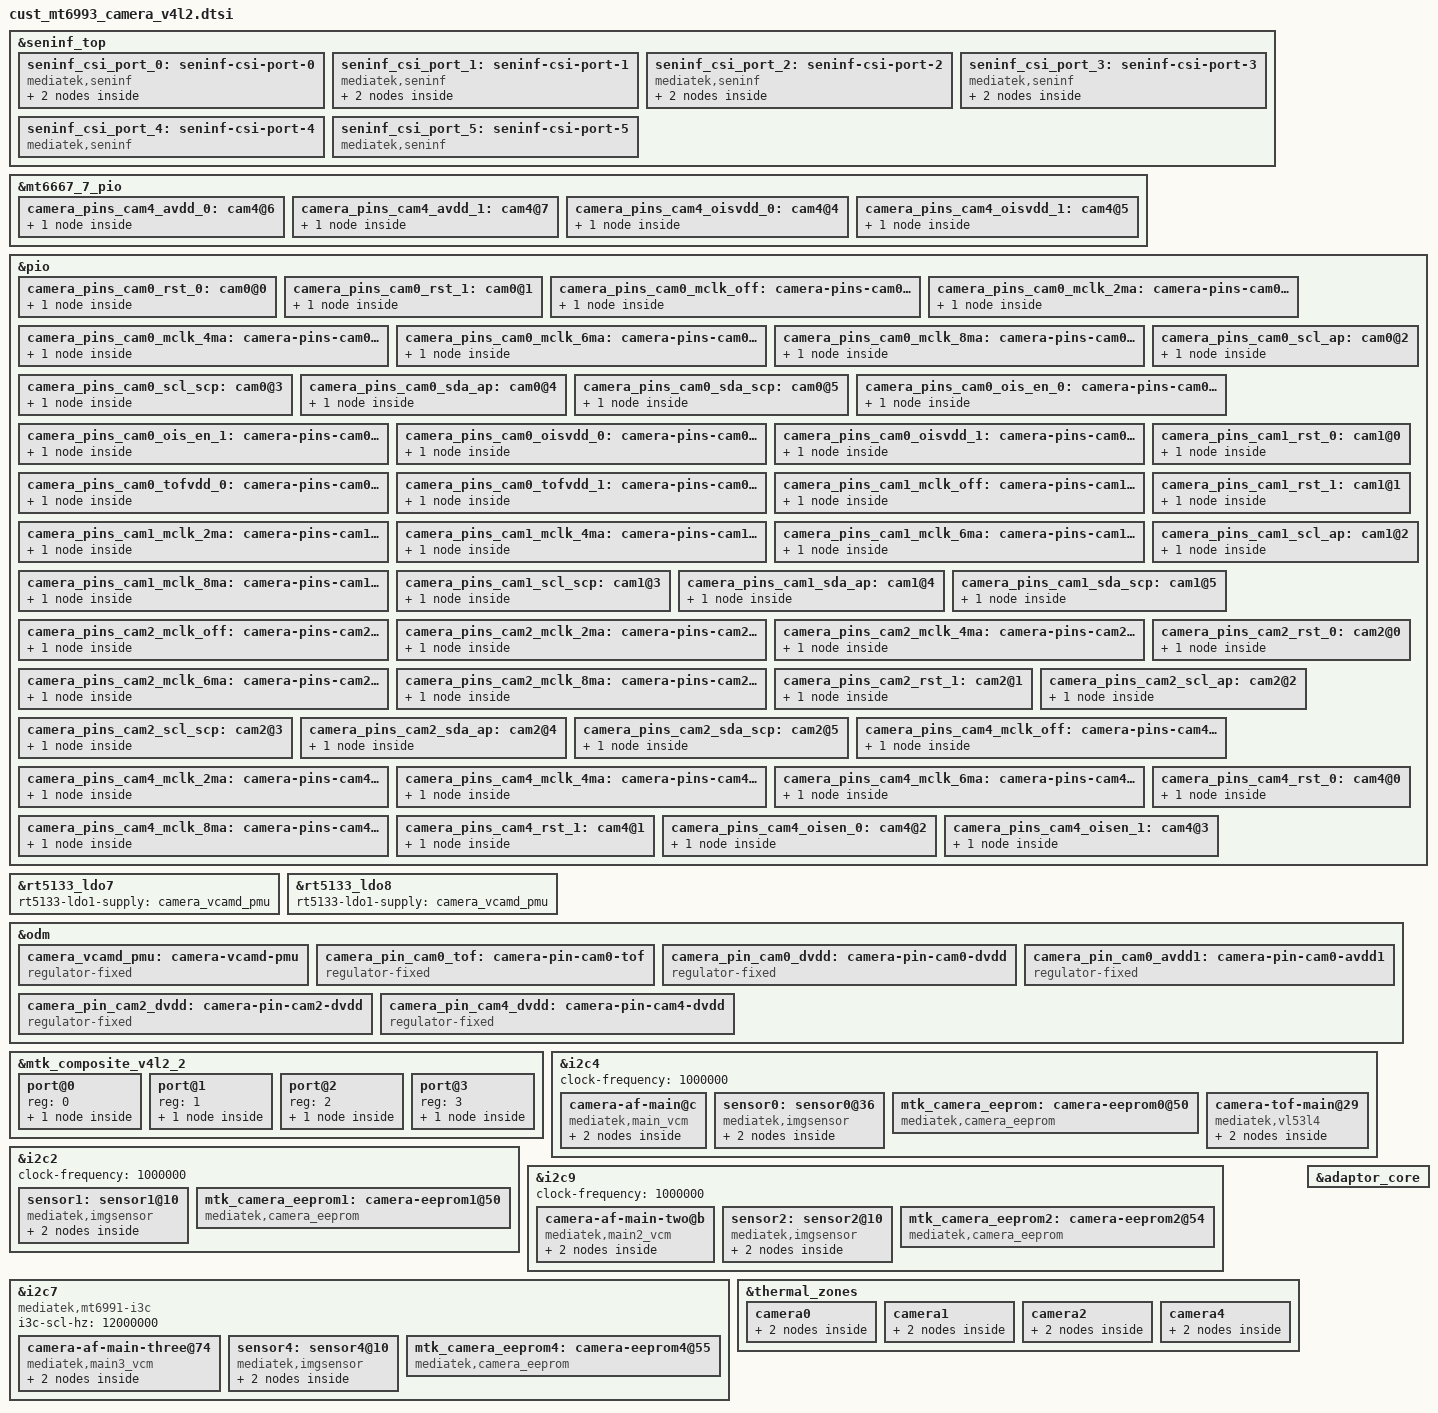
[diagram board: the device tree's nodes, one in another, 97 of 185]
// SPDX-License-Identifier: GPL-2.0
/* Copyright (c) 2023 MediaTek Inc. */
#include <dt-bindings/clock/mt6993-clk.h>
#include <dt-bindings/pinctrl/mt6993-pinfunc.h>
#include <dt-bindings/pinctrl/mt6667-pinfunc.h>

#if 0
&aov {
	depend-on = <&seninf_csi_port_0>,
		<&seninf_csi_port_1>,
		<&seninf_csi_port_2>,
		<&seninf_csi_port_3>,
		<&seninf_csi_port_4>;
};
#endif

&seninf_top {
		seninf_csi_port_0: seninf-csi-port-0 {
			compatible = "mediatek,seninf";
			csi-port = "0";

			nvmem-cells = <&csi_efuse0>;
			nvmem-cell-names = "rg_csi";
			port {
				seninf_csi_port_0_in: endpoint {
					remote-endpoint = <&sensor1_out>;
				};
			};
		};

		seninf_csi_port_1: seninf-csi-port-1 {
			compatible = "mediatek,seninf";
			csi-port = "1";

			nvmem-cells = <&csi_efuse1>;
			nvmem-cell-names = "rg_csi";

			/* HP9 EINT */
			interrupts-extended = <&pio 187 IRQ_TYPE_EDGE_FALLING>;
			gpio-num = <187>;
			eint-no = <3>; /* Max to 3, options:{1, 2, 3} */

			port {
				seninf_csi_port_1_in: endpoint {
					remote-endpoint = <&sensor4_out>;
				};
			};
		};

		seninf_csi_port_2: seninf-csi-port-2 {
			compatible = "mediatek,seninf";
			csi-port = "2";

			nvmem-cells = <&csi_efuse2>;
			nvmem-cell-names = "rg_csi";

			/* JN1 EINT */
			interrupts-extended = <&pio 186 IRQ_TYPE_EDGE_FALLING>;
			gpio-num = <186>;
			eint-no = <2>; /* Max to 3, options:{1, 2, 3} */

			port {
				seninf_csi_port_2_in: endpoint {
					remote-endpoint = <&sensor2_out>;
				};
			};
		};
		seninf_csi_port_3: seninf-csi-port-3 {
			compatible = "mediatek,seninf";
			csi-port = "3";

			nvmem-cells = <&csi_efuse3>;
			nvmem-cell-names = "rg_csi";

			/* KOKU EINT */
			interrupts-extended = <&pio 185 IRQ_TYPE_EDGE_FALLING>;
			gpio-num = <185>;
			eint-no = <1>; /* Max to 3, options:{1, 2, 3} */

			port {
				seninf_csi_port_3_in: endpoint@1 {
					remote-endpoint = <&sensor0_out>;
				};
			};
		};
		seninf_csi_port_4: seninf-csi-port-4 {
			compatible = "mediatek,seninf";
			csi-port = "4";

			nvmem-cells = <&csi_efuse4>;
			nvmem-cell-names = "rg_csi";
		};
		seninf_csi_port_5: seninf-csi-port-5 {
			compatible = "mediatek,seninf";
			csi-port = "5";

			nvmem-cells = <&csi_efuse5>;
			nvmem-cell-names = "rg_csi";
		};
};

&mt6667_7_pio {
	camera_pins_cam4_avdd_0: cam4@6 {
		pins-1 {
			pinmux = <PINMUX_MT6667_GPIO1__FUNC_GPIO1>;
			drive-strengh = <15>;
			output-low;
		};
	};

	camera_pins_cam4_avdd_1: cam4@7 {
		pins-1 {
			pinmux = <PINMUX_MT6667_GPIO1__FUNC_GPIO1>;
			drive-strengh = <15>;
			output-high;
		};
	};

	camera_pins_cam4_oisvdd_0: cam4@4 {
		pins-1 {
			pinmux = <PINMUX_MT6667_GPIO4__FUNC_GPIO4>;
			drive-strengh = <15>;
			output-low;
		};
	};
	camera_pins_cam4_oisvdd_1: cam4@5 {
		pins-1 {
			pinmux = <PINMUX_MT6667_GPIO4__FUNC_GPIO4>;
			drive-strengh = <15>;
			output-high;
		};
	};
};


&pio {
	camera_pins_cam0_rst_0: cam0@0 {
		pins-cmd-dat {
			pinmux = <PINMUX_GPIO206__FUNC_GPIO206>;
			slew-rate = <1>;
			output-low;
		};
	};

	camera_pins_cam0_rst_1: cam0@1 {
		pins-cmd-dat {
			pinmux = <PINMUX_GPIO206__FUNC_GPIO206>;
			slew-rate = <1>;
			output-high;
		};
	};

	camera_pins_cam0_mclk_off: camera-pins-cam0-mclk-off {
		pins-cmd-dat {
			pinmux = <PINMUX_GPIO73__FUNC_GPIO73>;
			drive-strength = <1>;
		};
	};

	camera_pins_cam0_mclk_2ma: camera-pins-cam0-mclk-2ma {
		pins-cmd-dat {
			pinmux = <PINMUX_GPIO73__FUNC_CMMCLK1>;
			drive-strength = <0>;
		};
	};

	camera_pins_cam0_mclk_4ma: camera-pins-cam0-mclk-4ma {
		pins-cmd-dat {
			pinmux = <PINMUX_GPIO73__FUNC_CMMCLK1>;
			drive-strength = <1>;
		};
	};

	camera_pins_cam0_mclk_6ma: camera-pins-cam0-mclk-6ma {
		pins-cmd-dat {
			pinmux = <PINMUX_GPIO73__FUNC_CMMCLK1>;
			drive-strength = <2>;
		};
	};

	camera_pins_cam0_mclk_8ma: camera-pins-cam0-mclk-8ma {
		pins-cmd-dat {
			pinmux = <PINMUX_GPIO73__FUNC_CMMCLK1>;
			drive-strength = <3>;
		};
	};

	camera_pins_cam0_scl_ap: cam0@2 {
		pins-cmd-dat {
			pinmux = <PINMUX_GPIO174__FUNC_SCL4>;
		};
	};
	camera_pins_cam0_scl_scp: cam0@3 {
		pins-cmd-dat {
			pinmux = <PINMUX_GPIO174__FUNC_SCP_SCL9>;
		};
	};
	camera_pins_cam0_sda_ap: cam0@4 {
		pins-cmd-dat {
			pinmux = <PINMUX_GPIO175__FUNC_SDA4>;
		};
	};
	camera_pins_cam0_sda_scp: cam0@5 {
		pins-cmd-dat {
			pinmux = <PINMUX_GPIO175__FUNC_SCP_SDA9>;
		};
	};
	camera_pins_cam0_ois_en_0: camera-pins-cam0-ois-en-0 {
		pins-cmd-dat {
			pinmux = <PINMUX_GPIO154__FUNC_GPIO154>;
			slew-rate = <1>;
			output-low;
		};
	};
	camera_pins_cam0_ois_en_1: camera-pins-cam0-ois-en-1 {
		pins-cmd-dat {
			pinmux = <PINMUX_GPIO154__FUNC_GPIO154>;
			slew-rate = <1>;
			output-high;
		};
	};
	camera_pins_cam0_oisvdd_0: camera-pins-cam0-oisvdd-0 {
		pins-cmd-dat {
			pinmux = <PINMUX_GPIO217__FUNC_GPIO217>;
			slew-rate = <1>;
			output-low;
		};
	};
	camera_pins_cam0_oisvdd_1: camera-pins-cam0-oisvdd-1 {
		pins-cmd-dat {
			pinmux = <PINMUX_GPIO217__FUNC_GPIO217>;
			slew-rate = <1>;
			output-high;
		};
	};
	camera_pins_cam0_tofvdd_0: camera-pins-cam0-tofvdd-0 {
		pins-cmd-dat {
			pinmux = <PINMUX_GPIO183__FUNC_GPIO183>;
			slew-rate = <1>;
			output-low;
		};
	};
	camera_pins_cam0_tofvdd_1: camera-pins-cam0-tofvdd-1 {
		pins-cmd-dat {
			pinmux = <PINMUX_GPIO183__FUNC_GPIO183>;
			slew-rate = <1>;
			output-high;
		};
	};
	camera_pins_cam1_mclk_off: camera-pins-cam1-mclk-off {
		pins-cmd-dat {
			pinmux = <PINMUX_GPIO72__FUNC_GPIO72>;
			drive-strength = <1>;
		};
	};
	camera_pins_cam1_mclk_2ma: camera-pins-cam1-mclk-2ma {
		pins-cmd-dat {
			pinmux = <PINMUX_GPIO72__FUNC_CMMCLK0>;
			drive-strength = <0>;
		};
	};
	camera_pins_cam1_mclk_4ma: camera-pins-cam1-mclk-4ma {
		pins-cmd-dat {
			pinmux = <PINMUX_GPIO72__FUNC_CMMCLK0>;
			drive-strength = <1>;
		};
	};
	camera_pins_cam1_mclk_6ma: camera-pins-cam1-mclk-6ma {
		pins-cmd-dat {
			pinmux = <PINMUX_GPIO72__FUNC_CMMCLK0>;
			drive-strength = <2>;
		};
	};
	camera_pins_cam1_mclk_8ma: camera-pins-cam1-mclk-8ma {
		pins-cmd-dat {
			pinmux = <PINMUX_GPIO72__FUNC_CMMCLK0>;
			drive-strength = <3>;
		};
	};
	camera_pins_cam1_rst_0: cam1@0 {
		pins-cmd-dat {
			pinmux = <PINMUX_GPIO205__FUNC_GPIO205>;
			slew-rate = <1>;
			output-low;
		};
	};
	camera_pins_cam1_rst_1: cam1@1 {
		pins-cmd-dat {
			pinmux = <PINMUX_GPIO205__FUNC_GPIO205>;
			slew-rate = <1>;
			output-high;
		};
	};
	camera_pins_cam1_scl_ap: cam1@2 {
		pins-cmd-dat {
			pinmux = <PINMUX_GPIO172__FUNC_SCL2>;
		};
	};
	camera_pins_cam1_scl_scp: cam1@3 {
		pins-cmd-dat {
			pinmux = <PINMUX_GPIO172__FUNC_SCP_SCL8>;
		};
	};
	camera_pins_cam1_sda_ap: cam1@4 {
		pins-cmd-dat {
			pinmux = <PINMUX_GPIO173__FUNC_SDA2>;
		};
	};
	camera_pins_cam1_sda_scp: cam1@5 {
		pins-cmd-dat {
			pinmux = <PINMUX_GPIO173__FUNC_SCP_SDA8>;
		};
	};
	camera_pins_cam2_mclk_off: camera-pins-cam2-mclk-off {
		pins-cmd-dat {
			pinmux = <PINMUX_GPIO208__FUNC_GPIO208>;
			drive-strength = <1>;
		};
	};
	camera_pins_cam2_mclk_2ma: camera-pins-cam2-mclk-2ma {
		pins-cmd-dat {
			pinmux = <PINMUX_GPIO208__FUNC_CMMCLK4>;
			drive-strength = <0>;
		};
	};
	camera_pins_cam2_mclk_4ma: camera-pins-cam2-mclk-4ma {
		pins-cmd-dat {
			pinmux = <PINMUX_GPIO208__FUNC_CMMCLK4>;
			drive-strength = <1>;
		};
	};
	camera_pins_cam2_mclk_6ma: camera-pins-cam2-mclk-6ma {
		pins-cmd-dat {
			pinmux = <PINMUX_GPIO208__FUNC_CMMCLK4>;
			drive-strength = <2>;
		};
	};
	camera_pins_cam2_mclk_8ma: camera-pins-cam2-mclk-8ma {
		pins-cmd-dat {
			pinmux = <PINMUX_GPIO208__FUNC_CMMCLK4>;
			drive-strength = <3>;
		};
	};
	camera_pins_cam2_rst_0: cam2@0 {
		pins-cmd-dat {
			pinmux = <PINMUX_GPIO207__FUNC_GPIO207>;
			slew-rate = <1>;
			output-low;
		};
	};
	camera_pins_cam2_rst_1: cam2@1 {
		pins-cmd-dat {
			pinmux = <PINMUX_GPIO207__FUNC_GPIO207>;
			slew-rate = <1>;
			output-high;
		};
	};
	camera_pins_cam2_scl_ap: cam2@2 {
		pins-cmd-dat {
			pinmux = <PINMUX_GPIO200__FUNC_SCL9>;
		};
	};
	camera_pins_cam2_scl_scp: cam2@3 {
		pins-cmd-dat {
			pinmux = <PINMUX_GPIO200__FUNC_SCP_SCL7>;
		};
	};
	camera_pins_cam2_sda_ap: cam2@4 {
		pins-cmd-dat {
			pinmux = <PINMUX_GPIO201__FUNC_SDA9>;
		};
	};
	camera_pins_cam2_sda_scp: cam2@5 {
		pins-cmd-dat {
			pinmux = <PINMUX_GPIO201__FUNC_SCP_SDA7>;
		};
	};
	camera_pins_cam4_mclk_off: camera-pins-cam4-mclk-off {
		pins-cmd-dat {
			pinmux = <PINMUX_GPIO188__FUNC_GPIO188>;
			drive-strength = <1>;
		};
	};
	camera_pins_cam4_mclk_2ma: camera-pins-cam4-mclk-2ma {
		pins-cmd-dat {
			pinmux = <PINMUX_GPIO188__FUNC_CMMCLK2>;
			drive-strength = <0>;
		};
	};
	camera_pins_cam4_mclk_4ma: camera-pins-cam4-mclk-4ma {
		pins-cmd-dat {
			pinmux = <PINMUX_GPIO188__FUNC_CMMCLK2>;
			drive-strength = <1>;
		};
	};
	camera_pins_cam4_mclk_6ma: camera-pins-cam4-mclk-6ma {
		pins-cmd-dat {
			pinmux = <PINMUX_GPIO188__FUNC_CMMCLK2>;
			drive-strength = <2>;
		};
	};
	camera_pins_cam4_mclk_8ma: camera-pins-cam4-mclk-8ma {
		pins-cmd-dat {
			pinmux = <PINMUX_GPIO188__FUNC_CMMCLK2>;
			drive-strength = <3>;
		};
	};
	camera_pins_cam4_rst_0: cam4@0 {
		pins-cmd-dat {
			pinmux = <PINMUX_GPIO189__FUNC_GPIO189>;
			slew-rate = <1>;
			output-low;
		};
	};
	camera_pins_cam4_rst_1: cam4@1 {
		pins-cmd-dat {
			pinmux = <PINMUX_GPIO189__FUNC_GPIO189>;
			slew-rate = <1>;
			output-high;
		};
	};
	camera_pins_cam4_oisen_0: cam4@2 {
		pins-cmd-dat {
			pinmux = <PINMUX_GPIO155__FUNC_GPIO155>;
			slew-rate = <1>;
			output-low;
		};
	};
	camera_pins_cam4_oisen_1: cam4@3 {
		pins-cmd-dat {
			pinmux = <PINMUX_GPIO155__FUNC_GPIO155>;
			slew-rate = <1>;
			output-high;
		};
	};
};

&rt5133_ldo7 {
	rt5133-ldo1-supply = <&camera_vcamd_pmu>;
};

&rt5133_ldo8 {
	rt5133-ldo1-supply = <&camera_vcamd_pmu>;
};

&odm {
	camera_vcamd_pmu: camera-vcamd-pmu {
		compatible = "regulator-fixed";
		regulator-name = "amera-vcamd-pmu";
		regulator-min-microvolt = <1800000>;
		regulator-max-microvolt = <1800000>;
		enable-active-high;
		gpio = <&pio 182 0x0>;
	};

	camera_pin_cam0_tof:camera-pin-cam0-tof {
		compatible = "regulator-fixed";
		regulator-name = "camera-pin-cam0-tof";
		regulator-min-microvolt = <1800000>;
		regulator-max-microvolt = <1800000>;
		enable-active-high;
		gpio = <&pio 184 0x0>;
	};

	camera_pin_cam0_dvdd:camera-pin-cam0-dvdd {
		compatible = "regulator-fixed";
		regulator-name = "camera-pin-cam0-dvdd";
		regulator-min-microvolt = <1800000>;
		regulator-max-microvolt = <1800000>;
		enable-active-high;
		gpio = <&pio 192 0x0>;
	};

	camera_pin_cam0_avdd1:camera-pin-cam0-avdd1 {
		compatible = "regulator-fixed";
		regulator-name = "camera-pin-cam0-avdd1";
		regulator-min-microvolt = <1800000>;
		regulator-max-microvolt = <1800000>;
		enable-active-high;
		gpio = <&pio 193 0x0>;
	};

	camera_pin_cam2_dvdd:camera-pin-cam2-dvdd {
		compatible = "regulator-fixed";
		regulator-name = "camera-pin-cam2-dvdd";
		regulator-min-microvolt = <1800000>;
		regulator-max-microvolt = <1800000>;
		enable-active-high;
		gpio = <&pio 212 0x0>;
	};

	camera_pin_cam4_dvdd:camera-pin-cam4-dvdd {
		compatible = "regulator-fixed";
		regulator-name = "camera-pin-cam4-dvdd";
		regulator-min-microvolt = <1800000>;
		regulator-max-microvolt = <1800000>;
		enable-active-high;
		gpio = <&pio 215 0x0>;
	};
};

&mtk_composite_v4l2_2 {
	#address-cells = <1>;
	#size-cells = <0>;
	port@0 {
		reg = <0>;
		main_af_endpoint: endpoint {
			remote-endpoint = <&main_af>;
		};
	};
	port@1 {
		reg = <1>;
		main_af_cam1_endpoint: endpoint {
			remote-endpoint = <&main_af_cam1>;
		};
	};
	port@2 {
		reg = <2>;
		main_af_cam2_endpoint: endpoint {
			remote-endpoint = <&main_af_cam2>;
		};
	};
	port@3 {
		reg = <3>;
		main_tof_endpoint: endpoint {
			remote-endpoint = <&main_tof>;
		};
	};
};

&i2c4 {
	status = "okay";
	clock-frequency = <1000000>;

	camera-af-main@c {
		compatible = "mediatek,main_vcm";
		reg = <0x0c 0 0>;
		vin-supply = <&rt5133_gpio1>;
		port {
			main_af: endpoint {
				remote-endpoint = <&main_af_endpoint>;
			};
		};
	};

	sensor0: sensor0@36 {
		compatible = "mediatek,imgsensor";
		sensor-names = "ov48b_mipi_raw",
					"imx06a_mipi_raw",
					"imx06c_mipi_raw";
		reg = <0x36 0 0>;
		maximum-pmic-delay = <4000>;

		#thermal-sensor-cells = <0>;

		pinctrl-names = "mclk_off",
				"mclk_2mA",
				"mclk_4mA",
				"mclk_6mA",
				"mclk_8mA",
				"rst_low",
				"rst_high",
				"scl_ap",
				"scl_scp",
				"sda_ap",
				"sda_scp",
				"oisvdd_off",
				"oisvdd_on",
				"oisen_off",
				"oisen_on";
		pinctrl-0 = <&camera_pins_cam0_mclk_off>;
		pinctrl-1 = <&camera_pins_cam0_mclk_2ma>;
		pinctrl-2 = <&camera_pins_cam0_mclk_4ma>;
		pinctrl-3 = <&camera_pins_cam0_mclk_6ma>;
		pinctrl-4 = <&camera_pins_cam0_mclk_8ma>;
		pinctrl-5 = <&camera_pins_cam0_rst_0>;
		pinctrl-6 = <&camera_pins_cam0_rst_1>;
		pinctrl-7 = <&camera_pins_cam0_scl_ap>;
		pinctrl-8 = <&camera_pins_cam0_scl_scp>;
		pinctrl-9 = <&camera_pins_cam0_sda_ap>;
		pinctrl-10 = <&camera_pins_cam0_sda_scp>;
		pinctrl-11 = <&camera_pins_cam0_oisvdd_0>;
		pinctrl-12 = <&camera_pins_cam0_oisvdd_1>;
		pinctrl-13 = <&camera_pins_cam0_ois_en_0>;
		pinctrl-14 = <&camera_pins_cam0_ois_en_1>;

		avdd-supply =  <&rt5133_ldo5>;  // 2.8V
		avdd1-supply =  <&camera_pin_cam0_avdd1>;  // 1.8V
		dvdd-supply = <&rt5133_ldo7>;  // 1.1v for ov48b
		dvdd1-supply = <&camera_pin_cam0_dvdd>;  // 0.81v for tri cam
		afvdd1-supply = <&rt5133_gpio1>;
		dovdd-supply = <&camera_vcamd_pmu>;  // iovdd 1.8v share
		base-supply = <&rt5133_base>;

		clocks = <&cksys_top_clk CKSYS_TOP_UNIVPLL_192M_D32>,
			<&cksys_top_clk CKSYS_TOP_UNIVPLL_192M_D16>,
			<&cksys_top_clk CKSYS_VLP_F26M_CK_D2>,
			<&cksys_top_clk CKSYS_TOP_UNIVPLL_192M_D10>,
			<&cksys_top_clk CKSYS_TOP_UNIVPLL_192M_D8>,
			<&cksys_top_clk CKSYS_TOP_UNIVPLL_D6_D16>,
			<&cksys_vlp_clk CKSYS_VLP_OSC3>,
			<&cksys_top_clk CKSYS_TOP_UNIVPLL_D6_D8>,
			<&cksys_vlp_clk VLP_CAMTG1_SEL>;

		clock-names = "6", "12", "13", "19.2", "24", "26", "26_ulposc", "52", "mclk";


		status = "okay";
		port {
			sensor0_out: endpoint {
				remote-endpoint = <&seninf_csi_port_3_in>;
			};
		};
	};

	mtk_camera_eeprom:camera-eeprom0@50 {
		compatible = "mediatek,camera_eeprom";
		reg = <0x50 0 0>;
		names = "imx06c_cust_eeprom",
			"ov48b_mtk_eeprom";
		status = "okay";
	};

	camera-tof-main@29 {
		compatible = "mediatek,vl53l4";
		reg = <0x29 0 0>;
		pinctrl-names = "mclk_off",
				"camera_tof_en_off",
				"camera_tof_en_on";
		pinctrl-0 = <&camera_pins_cam0_mclk_off>;
		pinctrl-1 = <&camera_pins_cam0_tofvdd_0>;
		pinctrl-2 = <&camera_pins_cam0_tofvdd_1>;
		vin-supply =  <&camera_pin_cam0_tof>;
		vdd-supply =  <&rt5133_ldo5>;
		port {
			main_tof: endpoint {
				remote-endpoint = <&main_tof_endpoint>;
			};
		};
	};
};

&i2c2 {
	status = "okay";
	clock-frequency = <1000000>;

	sensor1: sensor1@10 {
		compatible = "mediatek,imgsensor";
		sensor-names = "s5k3p9sp_mipi_raw";
		reg = <0x10>;
		maximum-pmic-delay = <4000>;

		#thermal-sensor-cells = <0>;

		pinctrl-names = "mclk_off",
				"mclk_2mA",
				"mclk_4mA",
				"mclk_6mA",
				"mclk_8mA",
				"rst_low",
				"rst_high",
				"scl_ap",
				"scl_scp",
				"sda_ap",
				"sda_scp";
		pinctrl-0 = <&camera_pins_cam1_mclk_off>;
		pinctrl-1 = <&camera_pins_cam1_mclk_2ma>;
		pinctrl-2 = <&camera_pins_cam1_mclk_4ma>;
		pinctrl-3 = <&camera_pins_cam1_mclk_6ma>;
		pinctrl-4 = <&camera_pins_cam1_mclk_8ma>;
		pinctrl-5 = <&camera_pins_cam1_rst_0>;
		pinctrl-6 = <&camera_pins_cam1_rst_1>;
		pinctrl-7 = <&camera_pins_cam1_scl_ap>;
		pinctrl-8 = <&camera_pins_cam1_scl_scp>;
		pinctrl-9 = <&camera_pins_cam1_sda_ap>;
		pinctrl-10 = <&camera_pins_cam1_sda_scp>;

		avdd-supply = <&rt5133_ldo3>;
		dvdd-supply = <&rt5133_gpio3>;
		dovdd-supply = <&camera_vcamd_pmu>;
		base-supply = <&rt5133_base>;

		clocks = <&cksys_top_clk CKSYS_TOP_UNIVPLL_192M_D32>,
			<&cksys_top_clk CKSYS_TOP_UNIVPLL_192M_D16>,
			<&cksys_top_clk CKSYS_VLP_F26M_CK_D2>,
			<&cksys_top_clk CKSYS_TOP_UNIVPLL_192M_D10>,
			<&cksys_top_clk CKSYS_TOP_UNIVPLL_192M_D8>,
			<&cksys_top_clk CKSYS_TOP_UNIVPLL_D6_D16>,
			<&cksys_vlp_clk CKSYS_VLP_OSC3>,
			<&cksys_top_clk CKSYS_TOP_UNIVPLL_D6_D8>,
			<&cksys_vlp_clk VLP_CAMTG0_SEL>;
		clock-names = "6", "12", "13", "19.2", "24", "26", "26_ulposc", "52", "mclk";

		status = "okay";
		port {
			sensor1_out: endpoint {
				remote-endpoint = <&seninf_csi_port_0_in>;
			};
		};
	};

	mtk_camera_eeprom1:camera-eeprom1@50 {
		compatible = "mediatek,camera_eeprom";
		reg = <0x50 0 0>;
		names = "s5k3p9sp_mtk_eeprom";
		status = "okay";
	};
};

&i2c9 {
	status = "okay";
	clock-frequency = <1000000>;

	camera-af-main-two@b {
		compatible = "mediatek,main2_vcm";
		reg = <0x0b>;
		vin-supply = <&rt5133_ldo2>;
		port {
			main_af_cam1: endpoint {
				remote-endpoint = <&main_af_cam1_endpoint>;
			};
		};
	};

	sensor2: sensor2@10 {
		compatible = "mediatek,imgsensor";
		sensor-names = "s5kjn1_mipi_raw";
		reg = <0x10>;
		maximum-pmic-delay = <4000>;

		cust-aov-csi-clk = <312>;

		#thermal-sensor-cells = <0>;

		pinctrl-names = "mclk_off",
				"mclk_2mA",
				"mclk_4mA",
				"mclk_6mA",
				"mclk_8mA",
				"rst_low",
				"rst_high",
				"scl_ap",
				"scl_scp",
				"sda_ap",
				"sda_scp";

		pinctrl-0 = <&camera_pins_cam2_mclk_off>;
		pinctrl-1 = <&camera_pins_cam2_mclk_2ma>;
		pinctrl-2 = <&camera_pins_cam2_mclk_4ma>;
		pinctrl-3 = <&camera_pins_cam2_mclk_6ma>;
		pinctrl-4 = <&camera_pins_cam2_mclk_8ma>;
		pinctrl-5 = <&camera_pins_cam2_rst_0>;
		pinctrl-6 = <&camera_pins_cam2_rst_1>;
		pinctrl-7 = <&camera_pins_cam2_scl_ap>;
		pinctrl-8 = <&camera_pins_cam2_scl_scp>;
		pinctrl-9 = <&camera_pins_cam2_sda_ap>;
		pinctrl-10 = <&camera_pins_cam2_sda_scp>;

		avdd-supply = <&rt5133_ldo3>;
		dvdd-supply = <&camera_pin_cam2_dvdd>;
		afvdd-supply = <&rt5133_ldo2>;
		dovdd-supply = <&camera_vcamd_pmu>;
		base-supply = <&rt5133_base>;

		clocks = <&cksys_top_clk CKSYS_TOP_UNIVPLL_192M_D32>,
			<&cksys_top_clk CKSYS_TOP_UNIVPLL_192M_D16>,
			<&cksys_top_clk CKSYS_VLP_F26M_CK_D2>,
			<&cksys_top_clk CKSYS_TOP_UNIVPLL_192M_D10>,
			<&cksys_top_clk CKSYS_TOP_UNIVPLL_192M_D8>,
			<&cksys_top_clk CKSYS_TOP_UNIVPLL_D6_D16>,
			<&cksys_top_clk CKSYS_TOP_OSC_D20>,
			<&cksys_top_clk CKSYS_TOP_UNIVPLL_D6_D8>,
			<&cksys_vlp_clk VLP_CAMTG4_SEL>;
		clock-names = "6", "12", "13", "19.2", "24", "26", "26_ulposc", "52", "mclk";

		status = "okay";
		port {
			sensor2_out: endpoint {
				remote-endpoint = <&seninf_csi_port_2_in>;
			};
		};
	};

	mtk_camera_eeprom2:camera-eeprom2@54 {
		compatible = "mediatek,camera_eeprom";
		reg = <0x54>;
		names = "s5kjn1_cust_eeprom";
		status = "okay";
	};
};

&i2c7 {
	compatible = "mediatek,mt6991-i3c";
	#address-cells = <3>;
	#size-cells = <0>;
	i3c-scl-hz = <12000000>;
	status = "okay";

	camera-af-main-three@74 {
		compatible = "mediatek,main3_vcm";
		reg = <0x74 0 0>;
		vin-supply = <&rt5133_ldo2>;
		port {
			main_af_cam2: endpoint {
				remote-endpoint = <&main_af_cam2_endpoint>;
			};
		};
	};

	sensor4: sensor4@10 {
		compatible = "mediatek,imgsensor";
		sensor-names = "s5khp9sp_mipi_raw";
		reg = <0x26 0x0216 0x1b730000>;
		assigned-address = <0x26>;
		pre-cfg-addr = <0x10>;
		maximum-pmic-delay = <4000>;

		#thermal-sensor-cells = <0>;

		pinctrl-names = "mclk_off",
				"mclk_2mA",
				"mclk_4mA",
				"mclk_6mA",
				"mclk_8mA",
				"rst_low",
				"rst_high",
				"oisvdd_off",
				"oisvdd_on",
				"avdd_off",
				"avdd_on",
				"oisen_off",
				"oisen_on";
		pinctrl-0 = <&camera_pins_cam4_mclk_off>;
		pinctrl-1 = <&camera_pins_cam4_mclk_2ma>;
		pinctrl-2 = <&camera_pins_cam4_mclk_4ma>;
		pinctrl-3 = <&camera_pins_cam4_mclk_6ma>;
		pinctrl-4 = <&camera_pins_cam4_mclk_8ma>;
		pinctrl-5 = <&camera_pins_cam4_rst_0>;
		pinctrl-6 = <&camera_pins_cam4_rst_1>;
		pinctrl-7 = <&camera_pins_cam4_oisvdd_0>;
		pinctrl-8 = <&camera_pins_cam4_oisvdd_1>;
		pinctrl-9 = <&camera_pins_cam4_avdd_0>;
		pinctrl-10 = <&camera_pins_cam4_avdd_1>;
		pinctrl-11 = <&camera_pins_cam4_oisen_0>;
		pinctrl-12 = <&camera_pins_cam4_oisen_1>;


		afvdd-supply = <&rt5133_ldo2>;
		dvdd-supply = <&camera_pin_cam4_dvdd>;
		dovdd-supply = <&camera_vcamd_pmu>;
		base-supply = <&rt5133_base>;

		clocks = <&cksys_top_clk CKSYS_TOP_UNIVPLL_192M_D32>,
			<&cksys_top_clk CKSYS_TOP_UNIVPLL_192M_D16>,
			<&cksys_top_clk CKSYS_VLP_F26M_CK_D2>,
			<&cksys_top_clk CKSYS_TOP_UNIVPLL_192M_D10>,
			<&cksys_top_clk CKSYS_TOP_UNIVPLL_192M_D8>,
			<&cksys_top_clk CKSYS_TOP_UNIVPLL_D6_D16>,
			<&cksys_top_clk CKSYS_TOP_OSC_D20>,
			<&cksys_top_clk CKSYS_TOP_UNIVPLL_D6_D8>,
			<&cksys_vlp_clk VLP_CAMTG2_SEL>;

		clock-names = "6", "12", "13", "19.2", "24", "26", "26_ulposc", "52", "mclk";


		status = "okay";
		port {
			sensor4_out: endpoint {
				remote-endpoint = <&seninf_csi_port_1_in>;
			};
		};
	};

	mtk_camera_eeprom4:camera-eeprom4@55 {
		compatible = "mediatek,camera_eeprom";
		reg = <0x55 0 0>;
		names = "s5khp9sp_cust_eeprom";
		status = "okay";
	};
};

&thermal_zones {
	camera0: camera0 {
		polling-delay = <0>;
		polling-delay-passive = <0>;
		thermal-sensors = <&sensor0>;
		trips {
			camera0_crit: camera0-crit {
				temperature = <120000>;
				hysteresis = <2000>;
				type = "passive";
			};
		};
	};
	camera1: camera1 {
		polling-delay = <0>;
		polling-delay-passive = <0>;
		thermal-sensors = <&sensor1>;
		trips {
			camera1_crit: camera1-crit {
				temperature = <120000>;
				hysteresis = <2000>;
				type = "passive";
			};
		};
	};
	camera2: camera2 {
		polling-delay = <0>;
		polling-delay-passive = <0>;
		thermal-sensors = <&sensor2>;
		trips {
			camera2_crit: camera2-crit {
				temperature = <120000>;
				hysteresis = <2000>;
				type = "passive";
			};
		};
	};
	camera4: camera4 {
		polling-delay = <0>;
		polling-delay-passive = <0>;
		thermal-sensors = <&sensor4>;
		trips {
			camera4_crit: camera4-crit {
				temperature = <120000>;
				hysteresis = <2000>;
				type = "passive";
			};
		};
	};
};

&adaptor_core {
	power1-supply = <&camera_vcamd_pmu>;
	power2-supply = <&rt5133_ldo7>;
	power3-supply = <&rt5133_ldo1>;
	mux-sel-ctrl-supply = <&rt5133_gpio2>;
};
